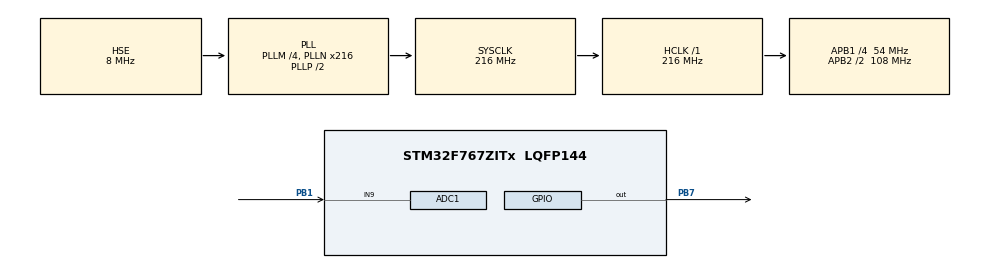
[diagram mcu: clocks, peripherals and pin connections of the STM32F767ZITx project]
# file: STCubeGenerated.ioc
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ADC1.Channel-0\#ChannelRegularConversion=ADC_CHANNEL_9
ADC1.ContinuousConvMode=ENABLE
ADC1.ExternalTrigConv=ADC_EXTERNALTRIGCONV_T2_TRGO
ADC1.NbrOfConversionFlag=1
ADC1.Rank-0\#ChannelRegularConversion=1
ADC1.SamplingTime-0\#ChannelRegularConversion=ADC_SAMPLETIME_3CYCLES
ADC1.master=1
Mcu.Family=STM32F7
Mcu.Name=STM32F767ZITx
Mcu.Package=LQFP144
NVIC.PriorityGroup=NVIC_PRIORITYGROUP_4
PB1.Signal=ADCx_IN9
PB7.Signal=GPIO_Output
PH0/OSC_IN.Mode=HSE-External-Clock-Source
PH0/OSC_IN.Signal=RCC_OSC_IN
PH1/OSC_OUT.Mode=HSE-External-Clock-Source
PH1/OSC_OUT.Signal=RCC_OSC_OUT
ProjectManager.HeapSize=0x200
ProjectManager.StackSize=0x400
ProjectManager.TargetToolchain=MDK-ARM V5
RCC.AHBFreq_Value=216000000
RCC.APB1CLKDivider=RCC_HCLK_DIV4
RCC.APB1Freq_Value=54000000
RCC.APB1TimFreq_Value=108000000
RCC.APB2CLKDivider=RCC_HCLK_DIV2
RCC.APB2Freq_Value=108000000
RCC.APB2TimFreq_Value=216000000
RCC.CortexFreq_Value=216000000
RCC.HCLKFreq_Value=216000000
RCC.HSE_VALUE=8000000
RCC.HSI_VALUE=16000000
RCC.LSE_VALUE=32768
RCC.PLLM=4
RCC.PLLN=216
RCC.PLLSourceVirtual=RCC_PLLSOURCE_HSE
RCC.SYSCLKFreq_VALUE=216000000
RCC.SYSCLKSource=RCC_SYSCLKSOURCE_PLLCLK
RCC.USBFreq_Value=216000000
RCC.VCOOutputFreq_Value=432000000
SH.ADCx_IN9.0=ADC1_IN9,IN9
TIM2.AutoReloadPreload=TIM_AUTORELOAD_PRELOAD_ENABLE
TIM2.Period=9999
TIM2.Prescaler=1079
TIM2.TIM_MasterOutputTrigger=TIM_TRGO_UPDATE
VP_TIM2_VS_ClockSourceINT.Mode=Internal
board=custom

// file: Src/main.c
/* USER CODE BEGIN Header */
/**
  ******************************************************************************
  * @file           : main.c
  * @brief          : Main program body
  ******************************************************************************
  * @attention
  *
  * <h2><center>&copy; Copyright (c) 2019 STMicroelectronics.
  * All rights reserved.</center></h2>
  *
  * This software component is licensed by ST under BSD 3-Clause license,
  * the "License"; You may not use this file except in compliance with the
  * License. You may obtain a copy of the License at:
  *                        opensource.org/licenses/BSD-3-Clause
  *
  ******************************************************************************
  */
/* USER CODE END Header */

#include "main.h"

/* USER CODE BEGIN Includes */
#include "cmsis_os2.h"                  // ::CMSIS:RTOS2
/* USER CODE END Includes */

ADC_HandleTypeDef hadc1;

TIM_HandleTypeDef htim2;

void SystemClock_Config(void);
static void MX_GPIO_Init(void);
static void MX_ADC1_Init(void);
static void MX_TIM2_Init(void);

int main(void)
{

  /* MCU Configuration--------------------------------------------------------*/

  /* Reset of all peripherals, Initializes the Flash interface and the Systick. */
  HAL_Init();

  /* Configure the system clock */
  SystemClock_Config();

  /* USER CODE BEGIN SysInit */
  osKernelInitialize();
  /* USER CODE END SysInit */

  /* Initialize all configured peripherals */
  MX_GPIO_Init();
  MX_ADC1_Init();
  MX_TIM2_Init();
  /* USER CODE BEGIN 2 */

  osKernelStart();
  /* USER CODE END 2 */

  /* Infinite loop */
  while (1)
  {

  }
}

void SystemClock_Config(void)
{
  RCC_OscInitTypeDef RCC_OscInitStruct = {0};
  RCC_ClkInitTypeDef RCC_ClkInitStruct = {0};

  /** Configure the main internal regulator output voltage
  */
  __HAL_RCC_PWR_CLK_ENABLE();
  __HAL_PWR_VOLTAGESCALING_CONFIG(PWR_REGULATOR_VOLTAGE_SCALE1);
  /** Initializes the CPU, AHB and APB busses clocks
  */
  RCC_OscInitStruct.OscillatorType = RCC_OSCILLATORTYPE_HSE;
  RCC_OscInitStruct.HSEState = RCC_HSE_BYPASS;
  RCC_OscInitStruct.PLL.PLLState = RCC_PLL_ON;
  RCC_OscInitStruct.PLL.PLLSource = RCC_PLLSOURCE_HSE;
  RCC_OscInitStruct.PLL.PLLM = 4;
  RCC_OscInitStruct.PLL.PLLN = 216;
  RCC_OscInitStruct.PLL.PLLP = RCC_PLLP_DIV2;
  RCC_OscInitStruct.PLL.PLLQ = 2;
  if (HAL_RCC_OscConfig(&RCC_OscInitStruct) != HAL_OK)
  {
    Error_Handler();
  }
  /** Activate the Over-Drive mode
  */
  if (HAL_PWREx_EnableOverDrive() != HAL_OK)
  {
    Error_Handler();
  }
  /** Initializes the CPU, AHB and APB busses clocks
  */
  RCC_ClkInitStruct.ClockType = RCC_CLOCKTYPE_HCLK|RCC_CLOCKTYPE_SYSCLK
                              |RCC_CLOCKTYPE_PCLK1|RCC_CLOCKTYPE_PCLK2;
  RCC_ClkInitStruct.SYSCLKSource = RCC_SYSCLKSOURCE_PLLCLK;
  RCC_ClkInitStruct.AHBCLKDivider = RCC_SYSCLK_DIV1;
  RCC_ClkInitStruct.APB1CLKDivider = RCC_HCLK_DIV4;
  RCC_ClkInitStruct.APB2CLKDivider = RCC_HCLK_DIV2;

  if (HAL_RCC_ClockConfig(&RCC_ClkInitStruct, FLASH_LATENCY_7) != HAL_OK)
  {
    Error_Handler();
  }
}

static void MX_ADC1_Init(void)
{

  ADC_ChannelConfTypeDef sConfig = {0};

  /** Configure the global features of the ADC (Clock, Resolution, Data Alignment and number of conversion)
  */
  hadc1.Instance = ADC1;
  hadc1.Init.ClockPrescaler = ADC_CLOCK_SYNC_PCLK_DIV4;
  hadc1.Init.Resolution = ADC_RESOLUTION_12B;
  hadc1.Init.ScanConvMode = ADC_SCAN_DISABLE;
  hadc1.Init.ContinuousConvMode = ENABLE;
  hadc1.Init.DiscontinuousConvMode = DISABLE;
  hadc1.Init.ExternalTrigConvEdge = ADC_EXTERNALTRIGCONVEDGE_RISING;
  hadc1.Init.ExternalTrigConv = ADC_EXTERNALTRIGCONV_T2_TRGO;
  hadc1.Init.DataAlign = ADC_DATAALIGN_RIGHT;
  hadc1.Init.NbrOfConversion = 1;
  hadc1.Init.DMAContinuousRequests = DISABLE;
  hadc1.Init.EOCSelection = ADC_EOC_SINGLE_CONV;
  if (HAL_ADC_Init(&hadc1) != HAL_OK)
  {
    Error_Handler();
  }
  /** Configure for the selected ADC regular channel its corresponding rank in the sequencer and its sample time.
  */
  sConfig.Channel = ADC_CHANNEL_9;
  sConfig.Rank = ADC_REGULAR_RANK_1;
  sConfig.SamplingTime = ADC_SAMPLETIME_3CYCLES;
  if (HAL_ADC_ConfigChannel(&hadc1, &sConfig) != HAL_OK)
  {
    Error_Handler();
  }

}

static void MX_TIM2_Init(void)
{

  TIM_ClockConfigTypeDef sClockSourceConfig = {0};
  TIM_MasterConfigTypeDef sMasterConfig = {0};

  htim2.Instance = TIM2;
  htim2.Init.Prescaler = 1079;
  htim2.Init.CounterMode = TIM_COUNTERMODE_UP;
  htim2.Init.Period = 9999;
  htim2.Init.ClockDivision = TIM_CLOCKDIVISION_DIV1;
  htim2.Init.AutoReloadPreload = TIM_AUTORELOAD_PRELOAD_ENABLE;
  if (HAL_TIM_Base_Init(&htim2) != HAL_OK)
  {
    Error_Handler();
  }
  sClockSourceConfig.ClockSource = TIM_CLOCKSOURCE_INTERNAL;
  if (HAL_TIM_ConfigClockSource(&htim2, &sClockSourceConfig) != HAL_OK)
  {
    Error_Handler();
  }
  sMasterConfig.MasterOutputTrigger = TIM_TRGO_UPDATE;
  sMasterConfig.MasterSlaveMode = TIM_MASTERSLAVEMODE_DISABLE;
  if (HAL_TIMEx_MasterConfigSynchronization(&htim2, &sMasterConfig) != HAL_OK)
  {
    Error_Handler();
  }

}

static void MX_GPIO_Init(void)
{
  GPIO_InitTypeDef GPIO_InitStruct = {0};

  /* GPIO Ports Clock Enable */
  __HAL_RCC_GPIOH_CLK_ENABLE();
  __HAL_RCC_GPIOB_CLK_ENABLE();

  /*Configure GPIO pin Output Level */
  HAL_GPIO_WritePin(GPIOB, GPIO_PIN_7, GPIO_PIN_RESET);

  /*Configure GPIO pin : PB7 */
  GPIO_InitStruct.Pin = GPIO_PIN_7;
  GPIO_InitStruct.Mode = GPIO_MODE_OUTPUT_PP;
  GPIO_InitStruct.Pull = GPIO_NOPULL;
  GPIO_InitStruct.Speed = GPIO_SPEED_FREQ_LOW;
  HAL_GPIO_Init(GPIOB, &GPIO_InitStruct);

}

void Error_Handler(void)
{
}

/************************ (C) COPYRIGHT STMicroelectronics *****END OF FILE****/
